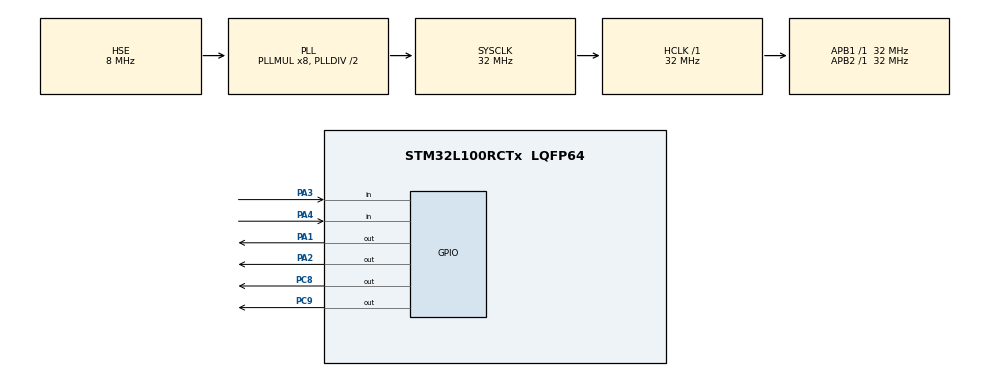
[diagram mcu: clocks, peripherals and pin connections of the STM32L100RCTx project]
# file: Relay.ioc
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Mcu.Family=STM32L1
Mcu.Name=STM32L100RCTx
Mcu.Package=LQFP64
NVIC.PriorityGroup=NVIC_PRIORITYGROUP_4
PA1.GPIO_PuPd=GPIO_NOPULL
PA1.PinState=GPIO_PIN_SET
PA1.Signal=GPIO_Output
PA2.GPIO_PuPd=GPIO_NOPULL
PA2.PinState=GPIO_PIN_SET
PA2.Signal=GPIO_Output
PA3.GPIO_PuPd=GPIO_PULLUP
PA3.Signal=GPIO_Input
PA4.GPIO_PuPd=GPIO_PULLUP
PA4.Signal=GPIO_Input
PC8.Signal=GPIO_Output
PC9.Signal=GPIO_Output
PH0-OSC_IN.Mode=HSE-External-Oscillator
PH0-OSC_IN.Signal=RCC_OSC_IN
PH1-OSC_OUT.Mode=HSE-External-Oscillator
PH1-OSC_OUT.Signal=RCC_OSC_OUT
ProjectManager.HeapSize=0x200
ProjectManager.StackSize=0x400
ProjectManager.TargetToolchain=SW4STM32
RCC.48MHZClocksFreq_Value=32000000
RCC.AHBFreq_Value=32000000
RCC.APB1Freq_Value=32000000
RCC.APB1TimFreq_Value=32000000
RCC.APB2Freq_Value=32000000
RCC.APB2TimFreq_Value=32000000
RCC.HCLKFreq_Value=32000000
RCC.HSE_VALUE=8000000
RCC.HSI_VALUE=16000000
RCC.LSE_VALUE=32768
RCC.MSI_VALUE=2097000
RCC.PLLMUL=RCC_PLL_MUL8
RCC.PLLSourceVirtual=RCC_PLLSOURCE_HSE
RCC.SYSCLKFreq_VALUE=32000000
RCC.SYSCLKSource=RCC_SYSCLKSOURCE_PLLCLK
RCC.VCOOutputFreq_Value=64000000
board=custom

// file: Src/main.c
/* USER CODE BEGIN Header */
/**
  ******************************************************************************
  * @file           : main.c
  * @brief          : Main program body
  ******************************************************************************
  * @attention
  *
  * <h2><center>&copy; Copyright (c) 2019 STMicroelectronics.
  * All rights reserved.</center></h2>
  *
  * This software component is licensed by ST under BSD 3-Clause license,
  * the "License"; You may not use this file except in compliance with the
  * License. You may obtain a copy of the License at:
  *                        opensource.org/licenses/BSD-3-Clause
  *
  ******************************************************************************
  */
/* USER CODE END Header */

#include "main.h"

void SystemClock_Config(void);
static void MX_GPIO_Init(void);

int main(void)
{

  /* MCU Configuration--------------------------------------------------------*/

  /* Reset of all peripherals, Initializes the Flash interface and the Systick. */
  HAL_Init();

  /* Configure the system clock */
  SystemClock_Config();

  /* Initialize all configured peripherals */
  MX_GPIO_Init();

  /* Infinite loop */
  /* USER CODE BEGIN WHILE */
  while (1)
  {
	  if (HAL_GPIO_ReadPin(GPIOA, GPIO_PIN_3) == 0) {
		  HAL_GPIO_WritePin(GPIOA, GPIO_PIN_1, 0);
		  if (HAL_GPIO_ReadPin(GPIOA, GPIO_PIN_4) == 0)
			  HAL_GPIO_WritePin(GPIOA, GPIO_PIN_2, 0);
		  else HAL_GPIO_WritePin(GPIOA, GPIO_PIN_2, 1);
	  }
	  else {
		  HAL_GPIO_WritePin(GPIOA, GPIO_PIN_1, 1);
		  HAL_GPIO_WritePin(GPIOA, GPIO_PIN_2, 1);
	  }
    /* USER CODE END WHILE */

  }
}

void SystemClock_Config(void)
{
  RCC_OscInitTypeDef RCC_OscInitStruct = {0};
  RCC_ClkInitTypeDef RCC_ClkInitStruct = {0};

  /** Configure the main internal regulator output voltage
  */
  __HAL_PWR_VOLTAGESCALING_CONFIG(PWR_REGULATOR_VOLTAGE_SCALE1);
  /** Initializes the CPU, AHB and APB busses clocks
  */
  RCC_OscInitStruct.OscillatorType = RCC_OSCILLATORTYPE_HSE;
  RCC_OscInitStruct.HSEState = RCC_HSE_ON;
  RCC_OscInitStruct.PLL.PLLState = RCC_PLL_ON;
  RCC_OscInitStruct.PLL.PLLSource = RCC_PLLSOURCE_HSE;
  RCC_OscInitStruct.PLL.PLLMUL = RCC_PLL_MUL8;
  RCC_OscInitStruct.PLL.PLLDIV = RCC_PLL_DIV2;
  if (HAL_RCC_OscConfig(&RCC_OscInitStruct) != HAL_OK)
  {
    Error_Handler();
  }
  /** Initializes the CPU, AHB and APB busses clocks
  */
  RCC_ClkInitStruct.ClockType = RCC_CLOCKTYPE_HCLK|RCC_CLOCKTYPE_SYSCLK
                              |RCC_CLOCKTYPE_PCLK1|RCC_CLOCKTYPE_PCLK2;
  RCC_ClkInitStruct.SYSCLKSource = RCC_SYSCLKSOURCE_PLLCLK;
  RCC_ClkInitStruct.AHBCLKDivider = RCC_SYSCLK_DIV1;
  RCC_ClkInitStruct.APB1CLKDivider = RCC_HCLK_DIV1;
  RCC_ClkInitStruct.APB2CLKDivider = RCC_HCLK_DIV1;

  if (HAL_RCC_ClockConfig(&RCC_ClkInitStruct, FLASH_LATENCY_1) != HAL_OK)
  {
    Error_Handler();
  }
}

static void MX_GPIO_Init(void)
{
  GPIO_InitTypeDef GPIO_InitStruct = {0};

  /* GPIO Ports Clock Enable */
  __HAL_RCC_GPIOH_CLK_ENABLE();
  __HAL_RCC_GPIOA_CLK_ENABLE();
  __HAL_RCC_GPIOC_CLK_ENABLE();

  /*Configure GPIO pin Output Level */
  HAL_GPIO_WritePin(GPIOA, GPIO_PIN_1|GPIO_PIN_2, GPIO_PIN_SET);

  /*Configure GPIO pin Output Level */
  HAL_GPIO_WritePin(GPIOC, GPIO_PIN_8|GPIO_PIN_9, GPIO_PIN_RESET);

  /*Configure GPIO pins : PA1 PA2 */
  GPIO_InitStruct.Pin = GPIO_PIN_1|GPIO_PIN_2;
  GPIO_InitStruct.Mode = GPIO_MODE_OUTPUT_PP;
  GPIO_InitStruct.Pull = GPIO_NOPULL;
  GPIO_InitStruct.Speed = GPIO_SPEED_FREQ_LOW;
  HAL_GPIO_Init(GPIOA, &GPIO_InitStruct);

  /*Configure GPIO pins : PA3 PA4 */
  GPIO_InitStruct.Pin = GPIO_PIN_3|GPIO_PIN_4;
  GPIO_InitStruct.Mode = GPIO_MODE_INPUT;
  GPIO_InitStruct.Pull = GPIO_PULLUP;
  HAL_GPIO_Init(GPIOA, &GPIO_InitStruct);

  /*Configure GPIO pins : PC8 PC9 */
  GPIO_InitStruct.Pin = GPIO_PIN_8|GPIO_PIN_9;
  GPIO_InitStruct.Mode = GPIO_MODE_OUTPUT_PP;
  GPIO_InitStruct.Pull = GPIO_NOPULL;
  GPIO_InitStruct.Speed = GPIO_SPEED_FREQ_LOW;
  HAL_GPIO_Init(GPIOC, &GPIO_InitStruct);

}

void Error_Handler(void)
{
}

/************************ (C) COPYRIGHT STMicroelectronics *****END OF FILE****/
